# STM32MP21_CM33 register map
File version: 0.4
CPU: CM33 r0p1, little endian, MPU, FPU, vendor SysTick, 8 interrupt priority bits
Registers are 32-bit, read-write, reset 0x0 unless marked. A register's access mark holds for its fields unless they carry their own. Offsets are from the block's base; [hi:lo] are bit positions; {n}, {i} and the like mark numbered series; 'fields as' and 'values as' point back to an identical list.

## OTFDEC — OTFDEC register bank
Base 0x40450000
Same registers: OTFDEC_S 0x50450000
0x00 OTFDEC_CR — OTFDEC control register
  [0] ENC — Encryption mode bit
    0=OTFDEC working in decryption mode; 1=OTFDEC working in encryption mode
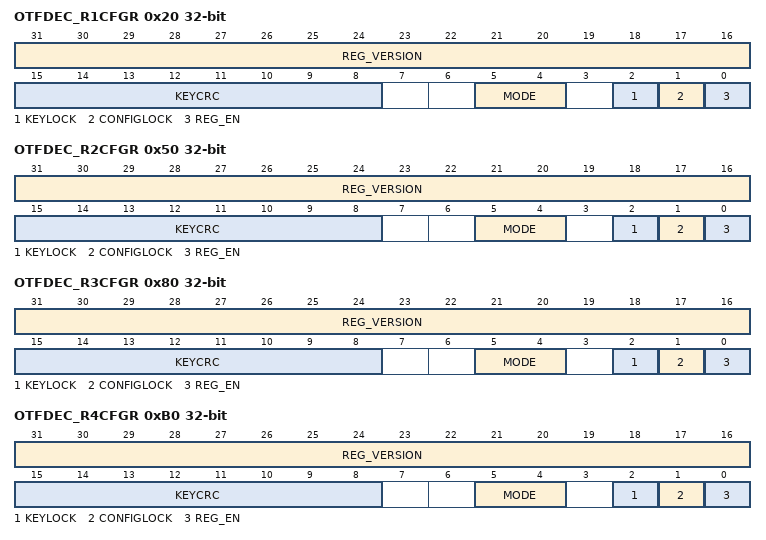
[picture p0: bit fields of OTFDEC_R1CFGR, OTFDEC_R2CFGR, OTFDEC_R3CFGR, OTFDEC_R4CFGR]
0x20 OTFDEC_R1CFGR — OTFDEC region 1 configuration register
  [31:16] REG_VERSION — region firmware version
  [15:8] KEYCRC ro — region key 8-bit CRC
  [5:4] MODE — operating mode
    2=All read accesses are decrypted (instruction or data); 3=Enhanced encryption mode is activated, and only instruction accesses are decrypted
  [2] KEYLOCK — region key lock
    0=Writes to this region KEYRx registers are allowed; 1=Writes to this region KEYRx registers are ignored until next OTFDEC reset
  [1] CONFIGLOCK — region config lock
    0=Writes to this region OTFDEC_RxCFGR, OTFDEC_RxSTARTADDR, OTFDEC_RxENDADDR and OTFDEC_RxNONCERy registers are allowed; 1=Writes to this region OTFDEC_RxCFGR, OTFDEC_RxSTARTADDR, OTFDEC_RxENDADDR and OTFDEC_RxNONCERy registers are ignored until next OTFDEC reset
  [0] REG_EN — region on-the-fly decryption enable
    0=On-the-fly decryption is disabled for this region; 1=On-the-fly decryption is enabled for this region
0x24 OTFDEC_R1STARTADDR — OTFDEC region 1 start address register
  [31:0] REG_START_ADDR — Region AHB start address
0x28 OTFDEC_R1ENDADDR reset 0xFFF — OTFDEC region 1 end address register
  [31:0] REG_END_ADDR — Region AHB end address
0x2C OTFDEC_R1NONCER0 — OTFDEC region 1 nonce register 0
  [31:0] REG_NONCE — Region nonce, bits [31:0]
{0x0+0x30*i} OTFDEC_R{i}NONCER1 (i=1..4) — OTFDEC region {i} nonce register 1
  [31:0] REG_NONCE — Region nonce, bits [63:32]
{0x4+0x30*i} OTFDEC_R{i}KEYR0 wo (i=1..4) — OTFDEC region {i} key register 0
  [31:0] REG_KEY — Region key, bits [31:0]
{0x8+0x30*i} OTFDEC_R{i}KEYR1 wo (i=1..4) — OTFDEC region {i} key register 1
  [31:0] REG_KEY — Region key, bits [63:32]
{0xC+0x30*i} OTFDEC_R{i}KEYR2 wo (i=1..4) — OTFDEC region {i} key register 2
  [31:0] REG_KEY — Region key, bits [95:64]
{0x10+0x30*i} OTFDEC_R{i}KEYR3 wo (i=1..4) — OTFDEC region {i} key register 3
  [31:0] REG_KEY — Region key, bits [127:96]
0x50 OTFDEC_R2CFGR — OTFDEC region 2 configuration register
  fields as OTFDEC_R1CFGR
0x54 OTFDEC_R2STARTADDR — OTFDEC region 2 start address register
  [31:0] REG_START_ADDR — Region AHB start address
0x58 OTFDEC_R2ENDADDR reset 0xFFF — OTFDEC region 2 end address register
  [31:0] REG_END_ADDR — Region AHB end address
0x5C OTFDEC_R2NONCER0 — OTFDEC region 2 nonce register 0
  [31:0] REG_NONCE — Region nonce, bits [31:0]
0x80 OTFDEC_R3CFGR — OTFDEC region 3 configuration register
  fields as OTFDEC_R1CFGR
0x84 OTFDEC_R3STARTADDR — OTFDEC region 3 start address register
  [31:0] REG_START_ADDR — Region AHB start address
0x88 OTFDEC_R3ENDADDR reset 0xFFF — OTFDEC region 3 end address register
  [31:0] REG_END_ADDR — Region AHB end address
0x8C OTFDEC_R3NONCER0 — OTFDEC region 3 nonce register 0
  [31:0] REG_NONCE — Region nonce, bits [31:0]
0xB0 OTFDEC_R4CFGR — OTFDEC region 4 configuration register
  fields as OTFDEC_R1CFGR
0xB4 OTFDEC_R4STARTADDR — OTFDEC region 4 start address register
  [31:0] REG_START_ADDR — Region AHB start address
0xB8 OTFDEC_R4ENDADDR reset 0xFFF — OTFDEC region 4 end address register
  [31:0] REG_END_ADDR — Region AHB end address
0xBC OTFDEC_R4NONCER0 — OTFDEC region 4 nonce register 0
  [31:0] REG_NONCE — Region nonce, bits [31:0]
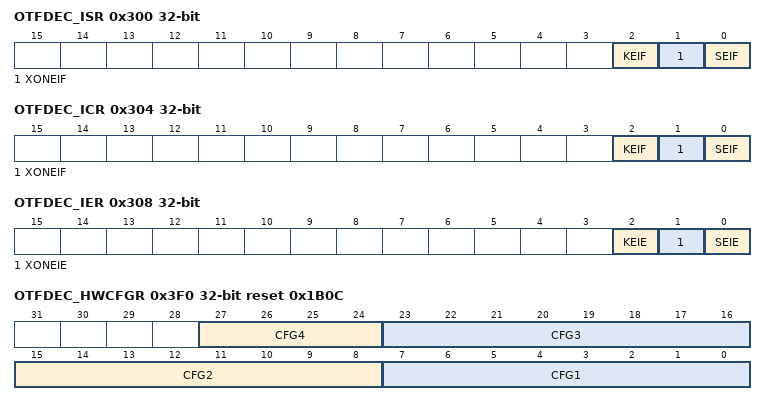
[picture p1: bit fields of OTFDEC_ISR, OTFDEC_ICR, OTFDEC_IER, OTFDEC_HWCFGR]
0x300 OTFDEC_ISR ro — OTFDEC interrupt status register
  [2] KEIF — Key error interrupt flag status
    0=OTFDEC operates properly; 1=Read access detected on an enabled encrypted region with its key registers null or not properly initialized (KEYCRC=0x0)
  [1] XONEIF — Execute-only execute-never error interrupt flag status
    0=No execute-only error status; 1=Read access detected on one region with MODE bits set to 11 or execute access detected while ENC=1
  [0] SEIF — Security error interrupt flag status
    0=No security error status; 1=Security error flag status, with interrupt pending
0x304 OTFDEC_ICR wo — OTFDEC interrupt clear register
  [2] KEIF — Key error interrupt flag clear
    0=KEIF flag status is not affected; 1=KEIF flag status is cleared in OTFDEC_ISR
  [1] XONEIF — Execute-only execute-never error interrupt flag clear
    0=XONEIF flag status is not affected; 1=XONEIF flag status is cleared in OTFDEC_ISR
  [0] SEIF — Security error interrupt flag clear
    0=SEIF flag status is not affected; 1=SEIF flag status is cleared in OTFDEC_ISR
0x308 OTFDEC_IER — OTFDEC interrupt enable register
  [2] KEIE — Key error interrupt enable
    0=Interrupt generation on key error flag KEIF is disabled (masked); 1=Interrupt generation on key error flag KEIF is enabled (not masked)
  [1] XONEIE — Execute-only execute-never error interrupt enable
    0=Interrupt generation on execute-only error XONEIF is disabled (masked); 1=Interrupt generation on execute-only error XONEIF is enabled (not masked)
  [0] SEIE — Security error interrupt enable
    0=Interrupt generation on security error SEIF is disabled (masked); 1=Interrupt generation on security error SEIF is enabled (not masked)
0x3F0 OTFDEC_HWCFGR ro reset 0x1B0C — OTFDEC hardware configuration register
  [27:24] CFG4 — Hardware Generic 4
  [23:16] CFG3 — Hardware Generic 3
  [15:8] CFG2 — Hardware Generic 2
  [7:0] CFG1 — Hardware Generic 1
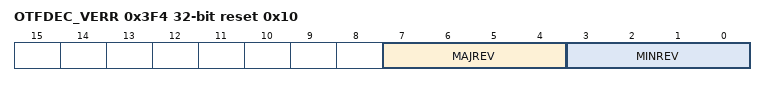
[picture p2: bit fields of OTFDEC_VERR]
0x3F4 OTFDEC_VERR ro reset 0x10 — OTFDEC version register
  [7:4] MAJREV — Major revision
  [3:0] MINREV — Minor revision
0x3F8 OTFDEC_IPIDR ro reset 0x170051 — OTFDEC identification register
  [31:0] ID — Identification code
0x3FC OTFDEC_SIDR ro reset 0xA3C5DD01 — OTFDEC size identification register
  [31:0] SID — Size identification code
